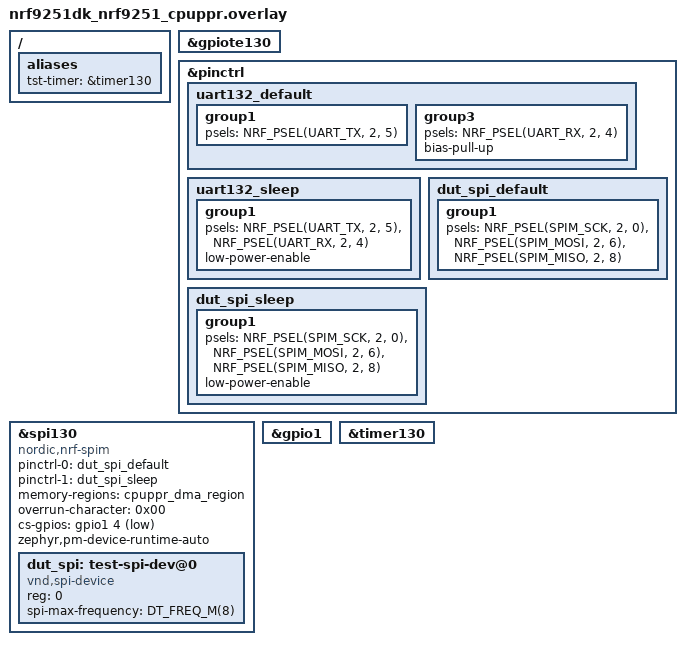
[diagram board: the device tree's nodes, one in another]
/*
 * Copyright (c) 2026 Nordic Semiconductor ASA
 *
 * SPDX-License-Identifier: LicenseRef-Nordic-5-Clause
 */

/* Required loopbacks:
 * P2.06 <-> P2.08
 */

/ {
	aliases {
		tst-timer = &timer130;
	};
};

&gpiote130 {
	status = "okay";
};

&pinctrl {
	/* Console without RTS/CTS, as P2.06 and P2.08 are used by the test. */
	uart132_default: uart132_default {
		group1 {
			psels = <NRF_PSEL(UART_TX, 2, 5)>;
		};

		group3 {
			psels = <NRF_PSEL(UART_RX, 2, 4)>;
			bias-pull-up;
		};
	};

	uart132_sleep: uart132_sleep {
		group1 {
			psels = <NRF_PSEL(UART_TX, 2, 5)>,
				<NRF_PSEL(UART_RX, 2, 4)>;
			low-power-enable;
		};
	};

	dut_spi_default: dut_spi_default {
		group1 {
			psels = <NRF_PSEL(SPIM_SCK, 2, 0)>,
				<NRF_PSEL(SPIM_MOSI, 2, 6)>,
				<NRF_PSEL(SPIM_MISO, 2, 8)>;
		};
	};

	dut_spi_sleep: dut_spi_sleep {
		group1 {
			psels = <NRF_PSEL(SPIM_SCK, 2, 0)>,
				<NRF_PSEL(SPIM_MOSI, 2, 6)>,
				<NRF_PSEL(SPIM_MISO, 2, 8)>;
			low-power-enable;
		};
	};
};

&spi130 {
	compatible = "nordic,nrf-spim";
	status = "okay";
	pinctrl-0 = <&dut_spi_default>;
	pinctrl-1 = <&dut_spi_sleep>;
	pinctrl-names = "default", "sleep";
	memory-regions = <&cpuppr_dma_region>;
	overrun-character = <0x00>;
	cs-gpios = <&gpio1 4 GPIO_ACTIVE_LOW>;
	zephyr,pm-device-runtime-auto;

	dut_spi: test-spi-dev@0 {
		compatible = "vnd,spi-device";
		reg = <0>;
		spi-max-frequency = <DT_FREQ_M(8)>;
	};
};

&gpio1 {
	status = "okay";
};

&timer130 {
	status = "okay";
};
